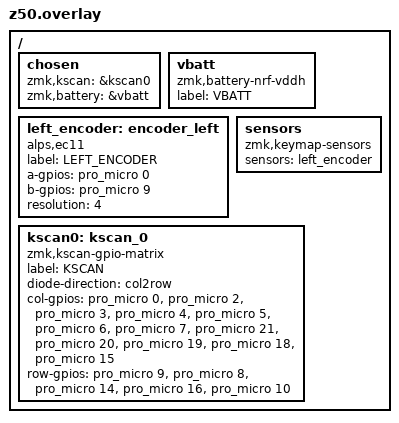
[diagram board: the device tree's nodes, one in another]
/{
    chosen {
        zmk,kscan = &kscan0;
        zmk,battery = &vbatt;
    };

    vbatt: vbatt {
        compatible = "zmk,battery-nrf-vddh";
        label = "VBATT";
    };

    left_encoder: encoder_left {
        compatible = "alps,ec11";
        label = "LEFT_ENCODER";
        a-gpios = <&pro_micro 0 (GPIO_ACTIVE_HIGH | GPIO_PULL_DOWN)>;
        b-gpios = <&pro_micro 9 (GPIO_ACTIVE_HIGH | GPIO_PULL_DOWN)>;
        resolution = <4>;
    };

    sensors {
        compatible = "zmk,keymap-sensors";
        sensors = <&left_encoder>;
    };

    kscan0: kscan_0 {
        compatible = "zmk,kscan-gpio-matrix";
        label = "KSCAN";
        diode-direction = "col2row";
        
        /* Columns */
        col-gpios
            /* Left-hand side */                        
            = <&pro_micro 0 GPIO_ACTIVE_HIGH>,
            <&pro_micro 2 GPIO_ACTIVE_HIGH>,
            <&pro_micro 3 GPIO_ACTIVE_HIGH>,
            <&pro_micro 4 GPIO_ACTIVE_HIGH>,
            <&pro_micro 5 GPIO_ACTIVE_HIGH>,
            <&pro_micro 6 GPIO_ACTIVE_HIGH>,
            <&pro_micro 7 GPIO_ACTIVE_HIGH>,
            /* Right-hand side */                        
            <&pro_micro 21 GPIO_ACTIVE_HIGH>,
            <&pro_micro 20 GPIO_ACTIVE_HIGH>,
            <&pro_micro 19 GPIO_ACTIVE_HIGH>,
            <&pro_micro 18 GPIO_ACTIVE_HIGH>,
            <&pro_micro 15 GPIO_ACTIVE_HIGH>;

        /* Rows */
        row-gpios
            = <&pro_micro 9 (GPIO_ACTIVE_HIGH | GPIO_PULL_DOWN)>,
            <&pro_micro 8 (GPIO_ACTIVE_HIGH | GPIO_PULL_DOWN)>,
            <&pro_micro 14 (GPIO_ACTIVE_HIGH | GPIO_PULL_DOWN)>,
            <&pro_micro 16 (GPIO_ACTIVE_HIGH | GPIO_PULL_DOWN)>,
            <&pro_micro 10 (GPIO_ACTIVE_HIGH | GPIO_PULL_DOWN)>;
    };

};

&left_encoder {
    status = "okay";
};
